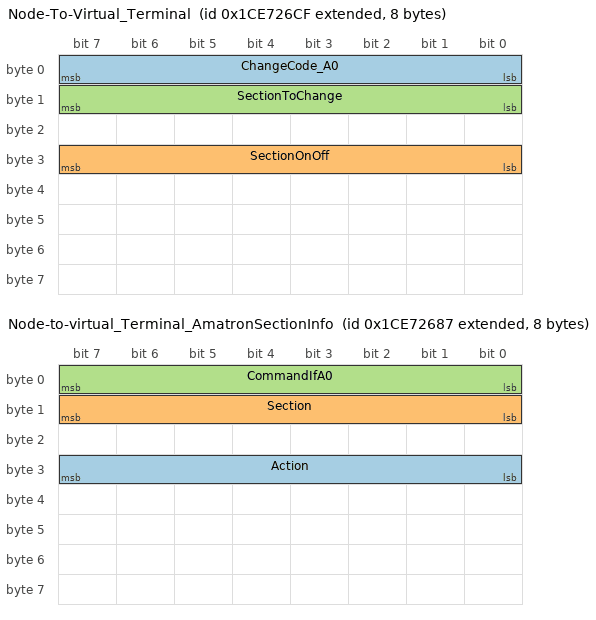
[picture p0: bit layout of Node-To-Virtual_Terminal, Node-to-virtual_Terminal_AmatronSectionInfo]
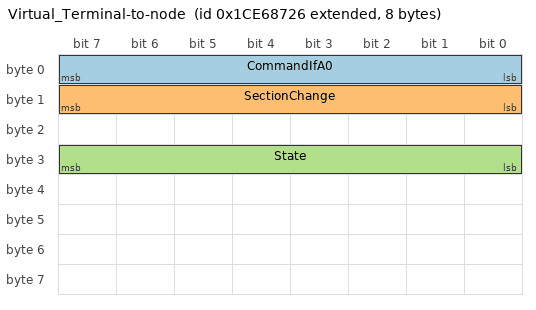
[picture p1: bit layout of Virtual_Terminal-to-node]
VERSION ""

NS_ :

BS_:
BU_: Amazone
BO_ 2632394447 Node-To-Virtual_Terminal: 8 Amazone
   SG_ ChangeCode_A0 : 7|8@0+ (1,0) [0|1] "" Amazone
   SG_ SectionOnOff : 31|8@0+ (1,0) [0|1] "" Amazone
   SG_ SectionToChange : 15|8@0+ (1,0) [0|1] "" Amazone

BO_ 2565275598 BORINGVirtual_Terminal-to-node_AMAClick_Data: 8 Amazone

BO_ 2565547655 Virtual_Terminal_(In_cab): 8 Amazone

BO_ 2632394375 Node-to-virtual_Terminal_AmatronSectionInfo: 8 Amazone
   SG_ Action : 31|8@0+ (1,0) [0|1] "" Amazone
   SG_ Section : 15|8@0+ (1,0) [0|1] "" Amazone
   SG_ CommandIfA0 : 7|8@0+ (1,0) [0|1] "" Amazone

BO_ 2633895303 Working_Set_Member: 8 Amazone

BO_ 2633895047 Working_Set_Member: 8 Amazone

BO_ 2632353574 Virtual_Terminal-to-node: 8 Amazone
   SG_ CommandIfA0 : 7|8@0+ (1,0) [0|1] "" Amazone
   SG_ SectionChange : 15|8@0+ (1,0) [0|1] "" Amazone
   SG_ State : 31|8@0+ (1,0) [0|1] "" Amazone

BO_ 2565537671 Request: 8 Amazone

BO_ 2565537790 Request: 8 Amazone

BO_ 2565799718 AddressClaimed: 8 Amazone

BO_ 2565799815 AddressClaimed: 8 Amazone

BO_ 2565799886 AddressClaimed: 8 Amazone

BO_ 2565799887 AddressClaimed: 8 Amazone

BO_ 2565799927 AddressClaimed: 8 Amazone

BO_ 2566786854 LanguageCommand: 8 Amazone

BO_ 2632384294 BORING_Virtual_Terminal-to-node: 8 Amazone

BA_DEF_ BO_ "GenMsgBackgroundColor" STRING ;
BA_DEF_ BO_ "GenMsgForegroundColor" STRING ;
BA_DEF_ BO_ "filterlabeling" INT 0 0;
BA_DEF_DEF_ "GenMsgBackgroundColor" "#ffffff";
BA_DEF_DEF_ "GenMsgForegroundColor" "#000000";
BA_DEF_DEF_ "filterlabeling" 1;
BA_ "GenMsgBackgroundColor" BO_ 2632394447 "#ffaaff";
BA_ "GenMsgBackgroundColor" BO_ 2565275598 "#787878";
BA_ "GenMsgBackgroundColor" BO_ 2632394375 "#ffaaff";
BA_ "GenMsgBackgroundColor" BO_ 2633895303 "#5555ff";
BA_ "GenMsgBackgroundColor" BO_ 2565537671 "#aa557f";
BA_ "GenMsgBackgroundColor" BO_ 2632384294 "#787878";
VAL_ 2632394447 ChangeCode_A0 160 "Intend_to_change";
VAL_ 2632394447 SectionOnOff 1 "On" 2 "Off";
VAL_ 2632394447 SectionToChange 249 "Section_1" 253 "Section_2" 1 "Section_3" 5 "Section_4" 9 "Section_5" 13 "Section_6" 17 "Section_7";
VAL_ 2632394375 Action 0 "Off" 1 "On";
VAL_ 2632394375 Section 249 "Section_1" 253 "Section_2" 1 "Section_3" 5 "Section_4" 9 "Section_5" 13 "Section_6" 17 "Section_7";
VAL_ 2632394375 CommandIfA0 160 "Command" 0 "";
VAL_ 2632353574 CommandIfA0 160 "Command";
VAL_ 2632353574 SectionChange 249 "Section_1" 253 "Section_2" 1 "Section_3" 5 "Section_4" 9 "Section_5" 13 "Section_6" 17 "Section_7";
VAL_ 2632353574 State 1 "On" 0 "Off" 0 "" 0 "" 0 "" 0 "" 0 "";
